# N32L406 register map
Vendor: Nsing Technologies Pte. Ltd.; File version: 1.0
Registers are 32-bit, read-write, reset 0x0 unless marked. A register's access mark holds for its fields unless they carry their own. Offsets are from the block's base; [hi:lo] are bit positions; {n}, {i} and the like mark numbered series; 'fields as' and 'values as' point back to an identical list.

## PWR — Power control
Base 0x40007000
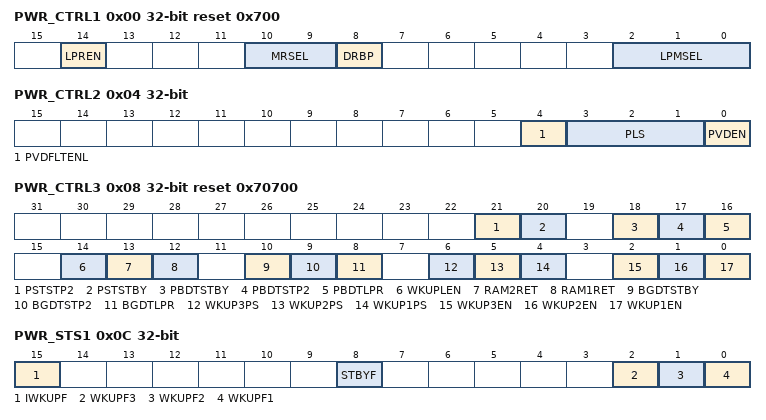
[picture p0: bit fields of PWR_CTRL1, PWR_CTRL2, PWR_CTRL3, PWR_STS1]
0x00 PWR_CTRL1 reset 0x700 — PWR_CTRL
  [14] LPREN, [10:9] MRSEL, [8] DRBP, [2:0] LPMSEL
0x04 PWR_CTRL2 — PWR_CTRL
  [4] PVDFLTENL — PVDFLTEN
  [3:1] PLS
  [0] PVDEN
0x08 PWR_CTRL3 reset 0x70700 (reset mask 0x37777) — PWR_CTRL
  [21] PSTSTP2, [20] PSTSTBY, [18] PBDTSTBY, [17] PBDTSTP2, [16] PBDTLPR, [14] WKUPLEN, [13] RAM2RET, [12] RAM1RET, [10] BGDTSTBY, [9] BGDTSTP2, [8] BGDTLPR, [6] WKUP3PS, [5] WKUP2PS, [4] WKUP1PS, [2] WKUP3EN, [1] WKUP2EN, [0] WKUP1EN
0x0C PWR_STS1 read — PWR_STS
  [15] IWKUPF, [8] STBYF, [2] WKUPF3, [1] WKUPF2, [0] WKUPF1
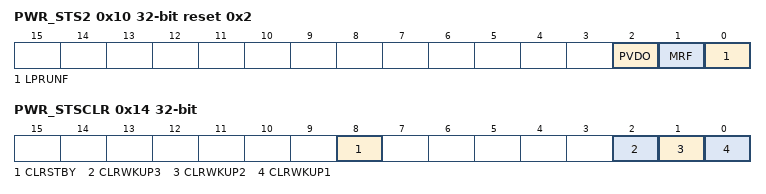
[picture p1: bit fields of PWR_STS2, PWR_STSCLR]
0x10 PWR_STS2 read reset 0x2 — PWR_STS
  [2] PVDO, [1] MRF, [0] LPRUNF
0x14 PWR_STSCLR write
  [8] CLRSTBY, [2] CLRWKUP3, [1] CLRWKUP2, [0] CLRWKUP1

## RCC — Reset and clock control
Base 0x40021000
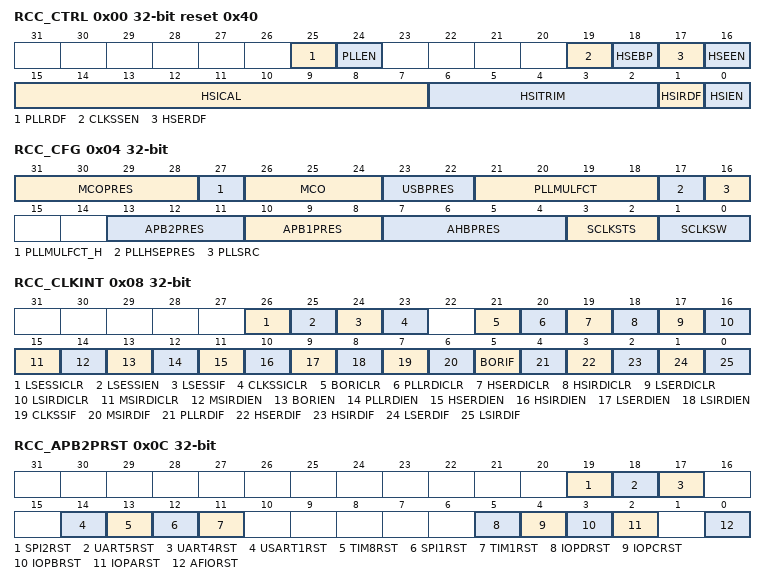
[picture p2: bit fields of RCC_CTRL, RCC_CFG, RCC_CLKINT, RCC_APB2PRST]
0x00 RCC_CTRL reset 0x40
  [25] PLLRDF, [24] PLLEN, [19] CLKSSEN, [18] HSEBP, [17] HSERDF, [16] HSEEN, [15:7] HSICAL, [6:2] HSITRIM, [1] HSIRDF, [0] HSIEN
0x04 RCC_CFG
  [31:28] MCOPRES, [27] PLLMULFCT_H, [26:24] MCO, [23:22] USBPRES, [21:18] PLLMULFCT, [17] PLLHSEPRES, [16] PLLSRC, [13:11] APB2PRES, [10:8] APB1PRES, [7:4] AHBPRES, [3:2] SCLKSTS, [1:0] SCLKSW
0x08 RCC_CLKINT
  [26] LSESSICLR, [25] LSESSIEN, [24] LSESSIF, [23] CLKSSICLR, [21] BORICLR, [20] PLLRDICLR, [19] HSERDICLR, [18] HSIRDICLR, [17] LSERDICLR, [16] LSIRDICLR, [15] MSIRDICLR, [14] MSIRDIEN, [13] BORIEN, [12] PLLRDIEN, [11] HSERDIEN, [10] HSIRDIEN, [9] LSERDIEN, [8] LSIRDIEN, [7] CLKSSIF, [6] MSIRDIF, [5] BORIF, [4] PLLRDIF, [3] HSERDIF, [2] HSIRDIF, [1] LSERDIF, [0] LSIRDIF
0x0C RCC_APB2PRST
  [19] SPI2RST, [18] UART5RST, [17] UART4RST, [14] USART1RST, [13] TIM8RST, [12] SPI1RST, [11] TIM1RST, [5] IOPDRST, [4] IOPCRST, [3] IOPBRST, [2] IOPARST, [0] AFIORST
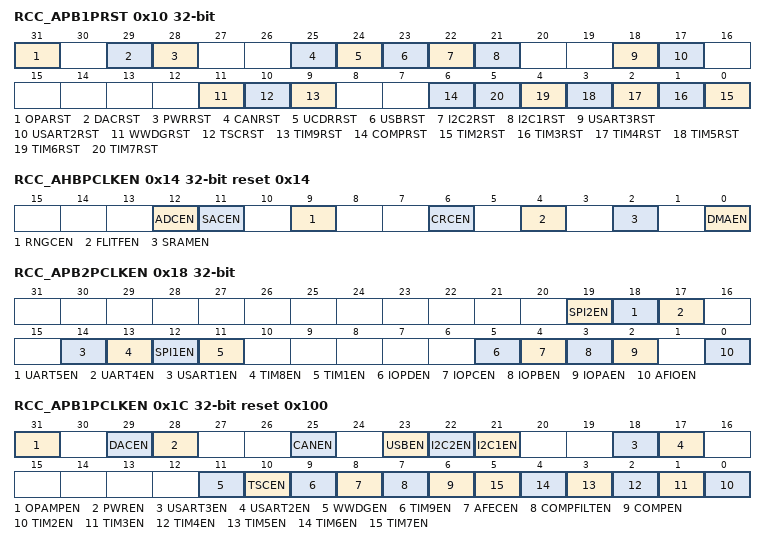
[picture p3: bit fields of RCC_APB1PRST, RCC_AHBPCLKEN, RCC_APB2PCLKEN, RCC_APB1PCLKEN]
0x10 RCC_APB1PRST
  [31] OPARST, [29] DACRST, [28] PWRRST, [25] CANRST, [24] UCDRRST, [23] USBRST, [22] I2C2RST, [21] I2C1RST, [18] USART3RST, [17] USART2RST, [11] WWDGRST, [10] TSCRST, [9] TIM9RST, [6] COMPRST, [n-2] TIM{n}RST (n=2..7)
0x14 RCC_AHBPCLKEN reset 0x14
  [12] ADCEN, [11] SACEN, [9] RNGCEN, [6] CRCEN, [4] FLITFEN, [2] SRAMEN, [0] DMAEN
0x18 RCC_APB2PCLKEN
  [19] SPI2EN, [18] UART5EN, [17] UART4EN, [14] USART1EN, [13] TIM8EN, [12] SPI1EN, [11] TIM1EN, [5] IOPDEN, [4] IOPCEN, [3] IOPBEN, [2] IOPAEN, [0] AFIOEN
0x1C RCC_APB1PCLKEN reset 0x100 (reset mask 0xB3E60E7F)
  [31] OPAMPEN, [29] DACEN, [28] PWREN, [25] CANEN, [23] USBEN, [22] I2C2EN, [21] I2C1EN, [18] USART3EN, [17] USART2EN, [11] WWDGEN, [10] TSCEN, [9] TIM9EN, [8] AFECEN, [7] COMPFILTEN, [6] COMPEN, [n-2] TIM{n}EN (n=2..7)
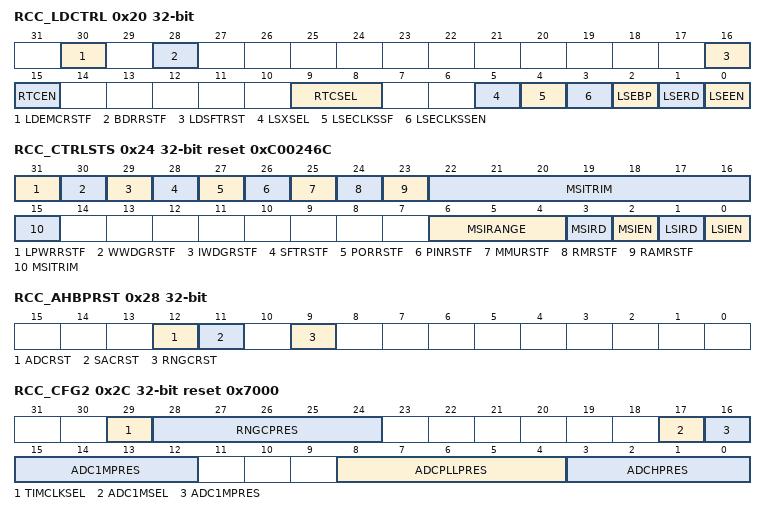
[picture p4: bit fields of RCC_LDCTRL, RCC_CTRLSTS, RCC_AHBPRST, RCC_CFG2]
0x20 RCC_LDCTRL
  [30] LDEMCRSTF, [28] BDRRSTF, [16] LDSFTRST, [15] RTCEN, [9:8] RTCSEL, [5] LSXSEL, [4] LSECLKSSF, [3] LSECLKSSEN, [2] LSEBP, [1] LSERD, [0] LSEEN
0x24 RCC_CTRLSTS reset 0xC00246C
  [31] LPWRRSTF, [30] WWDGRSTF, [29] IWDGRSTF, [28] SFTRSTF, [27] PORRSTF, [26] PINRSTF, [25] MMURSTF, [24] RMRSTF, [23] RAMRSTF, [22:15] MSITRIM, [6:4] MSIRANGE, [3] MSIRD, [2] MSIEN, [1] LSIRD, [0] LSIEN
0x28 RCC_AHBPRST
  [12] ADCRST, [11] SACRST, [9] RNGCRST
0x2C RCC_CFG2 reset 0x7000
  [29] TIMCLKSEL, [28:24] RNGCPRES, [17] ADC1MSEL, [16:12] ADC1MPRES, [8:4] ADCPLLPRES, [3:0] ADCHPRES
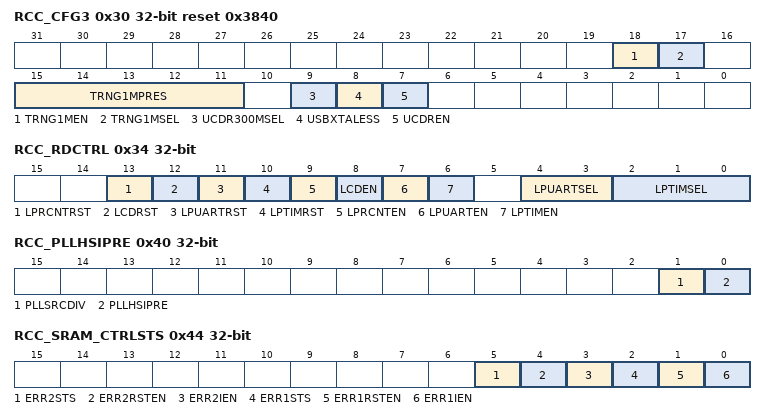
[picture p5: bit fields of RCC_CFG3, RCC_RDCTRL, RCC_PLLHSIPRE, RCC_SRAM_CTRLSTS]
0x30 RCC_CFG3 reset 0x3840
  [18] TRNG1MEN, [17] TRNG1MSEL, [15:11] TRNG1MPRES, [9] UCDR300MSEL, [8] USBXTALESS, [7] UCDREN
0x34 RCC_RDCTRL
  [13] LPRCNTRST, [12] LCDRST, [11] LPUARTRST, [10] LPTIMRST, [9] LPRCNTEN, [8] LCDEN, [7] LPUARTEN, [6] LPTIMEN, [4:3] LPUARTSEL, [2:0] LPTIMSEL
0x40 RCC_PLLHSIPRE
  [1] PLLSRCDIV, [0] PLLHSIPRE
0x44 RCC_SRAM_CTRLSTS
  [5] ERR2STS — ERR1STS
  [4] ERR2RSTEN — ERR1RSTEN
  [3] ERR2IEN — ERR1IEN
  [2] ERR1STS
  [1] ERR1RSTEN
  [0] ERR1IEN

## RTC — Real time clock
Base 0x40002800
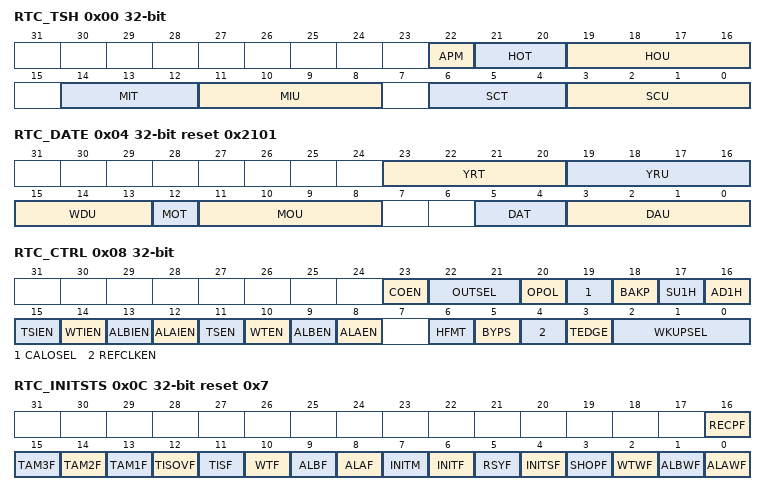
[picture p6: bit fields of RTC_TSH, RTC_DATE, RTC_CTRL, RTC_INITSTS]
0x00 RTC_TSH
  [22] APM, [21:20] HOT, [19:16] HOU, [14:12] MIT, [11:8] MIU, [6:4] SCT, [3:0] SCU
0x04 RTC_DATE reset 0x2101
  [23:20] YRT, [19:16] YRU, [15:13] WDU, [12] MOT, [11:8] MOU, [5:4] DAT, [3:0] DAU
0x08 RTC_CTRL
  [23] COEN, [22:21] OUTSEL, [20] OPOL, [19] CALOSEL, [18] BAKP, [17] SU1H, [16] AD1H, [15] TSIEN, [14] WTIEN, [13] ALBIEN, [12] ALAIEN, [11] TSEN, [10] WTEN, [9] ALBEN, [8] ALAEN, [6] HFMT, [5] BYPS, [4] REFCLKEN, [3] TEDGE, [2:0] WKUPSEL
0x0C RTC_INITSTS reset 0x7 (reset mask 0x17FFF)
  [16] RECPF, [15] TAM3F, [14] TAM2F, [13] TAM1F, [12] TISOVF, [11] TISF, [10] WTF, [9] ALBF, [8] ALAF, [7] INITM, [6] INITF, [5] RSYF, [4] INITSF, [3] SHOPF, [2] WTWF, [1] ALBWF, [0] ALAWF
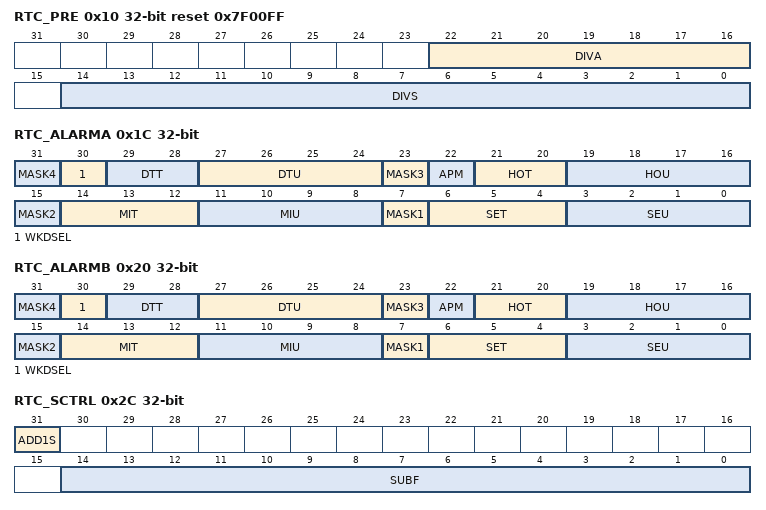
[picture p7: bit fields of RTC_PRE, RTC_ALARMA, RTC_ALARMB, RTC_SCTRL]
0x10 RTC_PRE reset 0x7F00FF
  [22:16] DIVA, [14:0] DIVS
0x14 RTC_WKUPT reset 0xFFFF
  [15:0] WKUPT
0x1C RTC_ALARMA
  [8n-1] MASK{n} (n=1..4), [30] WKDSEL, [29:28] DTT, [27:24] DTU, [22] APM, [21:20] HOT, [19:16] HOU, [14:12] MIT, [11:8] MIU, [6:4] SET, [3:0] SEU
0x20 RTC_ALARMB
  fields as RTC_ALARMA
0x24 RTC_WRP
  [7:0] PKEY
0x28 RTC_SUBS
  [15:0] SS
0x2C RTC_SCTRL
  [31] ADD1S, [14:0] SUBF
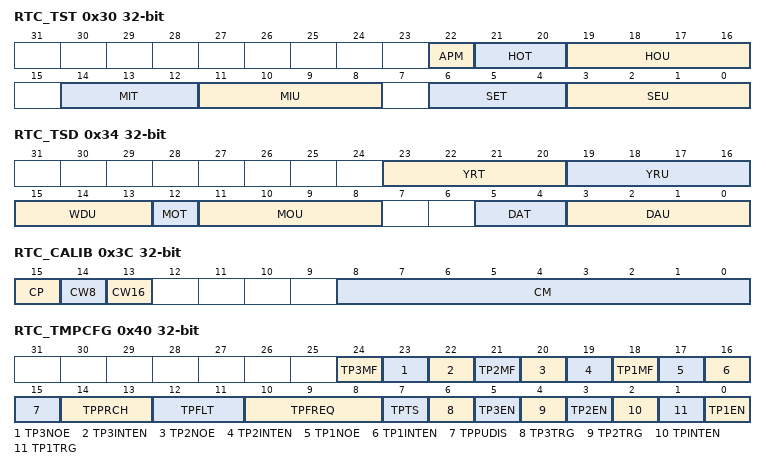
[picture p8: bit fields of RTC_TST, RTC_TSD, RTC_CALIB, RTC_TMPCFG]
0x30 RTC_TST (reset mask 0x7F)
  [22] APM, [21:20] HOT, [19:16] HOU, [14:12] MIT, [11:8] MIU, [6:4] SET, [3:0] SEU
0x34 RTC_TSD
  fields as RTC_DATE
0x38 RTC_TSSS
  [15:0] SSE
0x3C RTC_CALIB (reset mask 0xFF)
  [15] CP, [14] CW8, [13] CW16, [8:0] CM
0x40 RTC_TMPCFG (reset mask 0x2DFF9F)
  [24] TP3MF, [23] TP3NOE, [22] TP3INTEN, [21] TP2MF, [20] TP2NOE, [19] TP2INTEN, [18] TP1MF, [17] TP1NOE, [16] TP1INTEN, [15] TPPUDIS, [14:13] TPPRCH, [12:11] TPFLT, [10:8] TPFREQ, [7] TPTS, [6] TP3TRG, [5] TP3EN, [4] TP2TRG, [3] TP2EN, [2] TPINTEN, [1] TP1TRG, [0] TP1EN
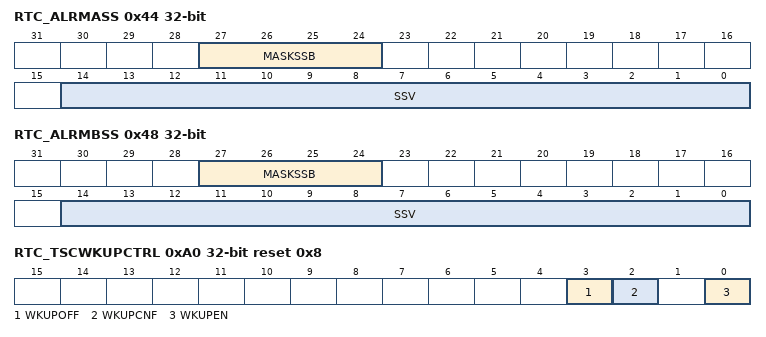
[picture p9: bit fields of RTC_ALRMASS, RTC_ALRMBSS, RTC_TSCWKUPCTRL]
0x44 RTC_ALRMASS
  [27:24] MASKSSB, [14:0] SSV
0x48 RTC_ALRMBSS
  [27:24] MASKSSB, [14:0] SSV
0x4C RTC_OPT
  [0] TYPE
{0x4C+4i} RTC_BKP{i} (i=1..20)
  [31:0] BF
0xA0 RTC_TSCWKUPCTRL reset 0x8
  [3] WKUPOFF, [2] WKUPCNF, [0] WKUPEN
0xA4 RTC_TSCWKUPCNT reset 0x2FE
  [13:0] CNT
